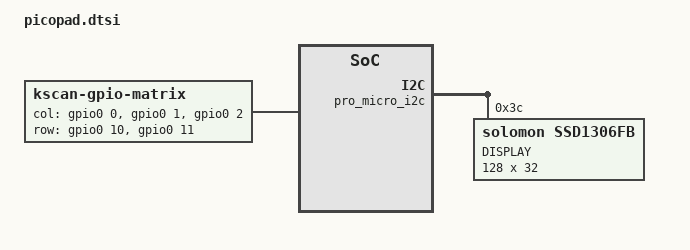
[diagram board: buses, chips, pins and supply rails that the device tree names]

/*
 * Copyright (c) 2022 The ZMK Contributors
 *
 * SPDX-License-Identifier: MIT
 */

#include <dt-bindings/zmk/matrix_transform.h>

/ {
    chosen {
        zephyr,display = &oled;
        zmk,kscan = &kscan0;
    };

    kscan0: kscan {
        compatible = "zmk,kscan-gpio-matrix";
        label = "KSCAN";
        diode-direction = "col2row";

        col-gpios
            = <&gpio0 0 GPIO_ACTIVE_HIGH>
            , <&gpio0 1 GPIO_ACTIVE_HIGH>
            , <&gpio0 2 GPIO_ACTIVE_HIGH>
            ;

        row-gpios
            = <&gpio0 10 (GPIO_ACTIVE_HIGH | GPIO_PULL_DOWN)>
            , <&gpio0 11 (GPIO_ACTIVE_HIGH | GPIO_PULL_DOWN)>
            ;
    };
 };

&pro_micro_i2c {
    status = "okay";

    oled: ssd1306@3c {
        compatible = "solomon,ssd1306fb";
        reg = <0x3c>;
        label = "DISPLAY";
        width = <128>;
        height = <32>;
        segment-offset = <0>;
        page-offset = <0>;
        display-offset = <0>;
        multiplex-ratio = <31>;
        segment-remap;
        com-invdir;
        com-sequential;
        prechargep = <0x22>;
    };
};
